# MKM33ZA5 register map
Vendor: Freescale Semiconductor, Inc.; Series: Kinetis_M; File version: 1.6
CPU: CM0PLUS r0p0, little endian, no MPU, no FPU, VTOR, 2 interrupt priority bits
Registers are 8-bit, read-write, reset 0x0 unless marked. A register's access mark holds for its fields unless they carry their own. Offsets are from the block's base; [hi:lo] are bit positions; {n}, {i} and the like mark numbered series.

## XBAR — Crossbar Switch
Base 0x40055000; register names take the prefix XBAR_
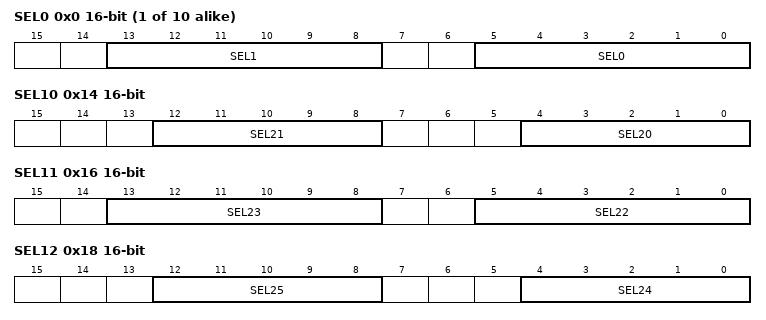
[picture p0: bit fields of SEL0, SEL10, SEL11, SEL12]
{0x0+2i} SEL{i} 16-bit (i=0..9) — Crossbar Select Register {i}
  [13:8] SEL{2i+1}, [5:0] SEL{2i}
0x14 SEL10 16-bit — Crossbar Select Register 10
  [12:8] SEL21, [4:0] SEL20
0x16 SEL11 16-bit — Crossbar Select Register 11
  [13:8] SEL23, [5:0] SEL22
0x18 SEL12 16-bit — Crossbar Select Register 12
  [12:8] SEL25, [4:0] SEL24
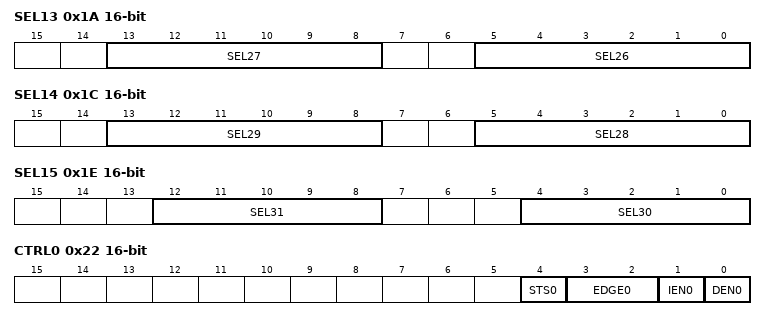
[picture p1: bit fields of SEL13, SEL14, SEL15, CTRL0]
0x1A SEL13 16-bit — Crossbar Select Register 13
  [13:8] SEL27, [5:0] SEL26
0x1C SEL14 16-bit — Crossbar Select Register 14
  [13:8] SEL29, [5:0] SEL28
0x1E SEL15 16-bit — Crossbar Select Register 15
  [12:8] SEL31, [4:0] SEL30
0x20 SEL16 16-bit — Crossbar Select Register 16
  [5:0] SEL32
0x22 CTRL0 16-bit — Crossbar Control Register 0
  [4] STS0 — Edge detection status for XBAR_OUT0
    0=Active edge not yet detected on XBAR_OUT0; 1=Active edge detected on XBAR_OUT0
  [3:2] EDGE0 — Active edge for edge detection on XBAR_OUT0
    0=STS0 never asserts; 1=STS0 asserts on rising edges of XBAR_OUT0; 2=STS0 asserts on falling edges of XBAR_OUT0; 3=STS0 asserts on rising and falling edges of XBAR_OUT0
  [1] IEN0 — Interrupt Enable for XBAR_OUT0
    0=Interrupt disabled; 1=Interrupt enabled
  [0] DEN0 — DMA Enable for XBAR_OUT0
    0=DMA disabled; 1=DMA enabled

## EWM — External Watchdog Monitor
Base 0x40061000; register names take the prefix EWM_
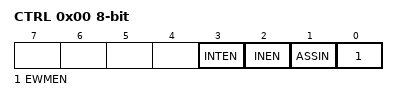
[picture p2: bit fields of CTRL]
0x00 CTRL — Control Register
  [3] INTEN — Interrupt Enable.
  [2] INEN — Input Enable.
  [1] ASSIN — EWM_in's Assertion State Select.
  [0] EWMEN — EWM enable.
0x01 SERV wo — Service Register
  [7:0] SERVICE
0x02 CMPL — Compare Low Register
  [7:0] COMPAREL
0x03 CMPH reset 0xFF — Compare High Register
  [7:0] COMPAREH

## OSC — Oscillator
Base 0x40066000; register names take the prefix OSC_
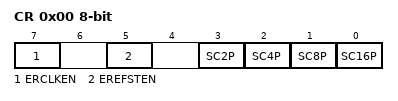
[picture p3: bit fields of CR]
0x00 CR — OSC Control Register
  [7] ERCLKEN — External Reference Enable
    0=External reference clock is inactive; 1=External reference clock is enabled
  [5] EREFSTEN — External Reference Stop Enable
    0=External reference clock is disabled in Stop mode; 1=External reference clock stays enabled in Stop mode if ERCLKEN is set before entering Stop mode
  [3] SC2P — Oscillator 2 pF Capacitor Load Configure
    0=Disable the selection; 1=Add 2 pF capacitor to the oscillator load
  [2] SC4P — Oscillator 4 pF Capacitor Load Configure
    0=Disable the selection; 1=Add 4 pF capacitor to the oscillator load
  [1] SC8P — Oscillator 8 pF Capacitor Load Configure
    0=Disable the selection; 1=Add 8 pF capacitor to the oscillator load
  [0] SC16P — Oscillator 16 pF Capacitor Load Configure
    0=Disable the selection; 1=Add 16 pF capacitor to the oscillator load

## VREF — Voltage Reference
Base 0x4006F000; register names take the prefix VREF_
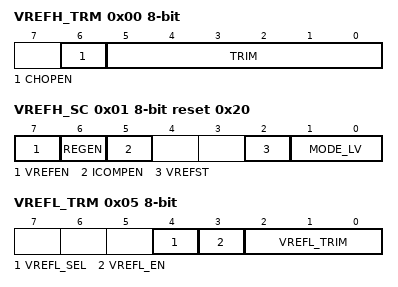
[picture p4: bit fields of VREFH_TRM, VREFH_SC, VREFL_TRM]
0x00 VREFH_TRM (reset mask 0x40) — VREF Trim Register
  [6] CHOPEN — Chop oscillator enable. When set, internal chopping operation is enabled and the internal analog offset will be minimized.
    0=Chop oscillator is disabled; 1=Chop oscillator is enabled
  [5:0] TRIM — Trim bits
    0=Min; 63=Max
0x01 VREFH_SC reset 0x20 — VREF Status and Control Register
  [7] VREFEN — Internal Voltage Reference enable
    0=The module is disabled; 1=The module is enabled
  [6] REGEN — Regulator enable
    0=Internal 1.75 V regulator is disabled; 1=Internal 1.75 V regulator is enabled
  [5] ICOMPEN — Second order curvature compensation enable
    0=Disabled; 1=Enabled
  [2] VREFST ro — Internal Voltage Reference stable
    0=The module is disabled or not stable; 1=The module is stable
  [1:0] MODE_LV — Buffer Mode selection
    0=Bandgap on only, for stabilization and startup; 1=High power buffer mode enabled; 2=Low-power buffer mode enabled
0x05 VREFL_TRM (reset mask 0xF8) — VREFL TRIM Register
  [4] VREFL_SEL
    0=Internal reference; 1=External reference
  [3] VREFL_EN
    0=Disable; 1=Enable
  [2:0] VREFL_TRIM

## Notices in the file
Redistribution and use in source and binary forms, with or without modification,
are permitted provided that the following conditions are met:
o Redistributions of source code must retain the above copyright notice, this list
of conditions and the following disclaimer.
o Redistributions in binary form must reproduce the above copyright notice, this
list of conditions and the following disclaimer in the documentation and/or
other materials provided with the distribution.
o Neither the name of Freescale Semiconductor, Inc. nor the names of its
contributors may be used to endorse or promote products derived from this
software without specific prior written permission.
THIS SOFTWARE IS PROVIDED BY THE COPYRIGHT HOLDERS AND CONTRIBUTORS "AS IS" AND
ANY EXPRESS OR IMPLIED WARRANTIES, INCLUDING, BUT NOT LIMITED TO, THE IMPLIED
WARRANTIES OF MERCHANTABILITY AND FITNESS FOR A PARTICULAR PURPOSE ARE
DISCLAIMED. IN NO EVENT SHALL THE COPYRIGHT HOLDER OR CONTRIBUTORS BE LIABLE FOR
ANY DIRECT, INDIRECT, INCIDENTAL, SPECIAL, EXEMPLARY, OR CONSEQUENTIAL DAMAGES
(INCLUDING, BUT NOT LIMITED TO, PROCUREMENT OF SUBSTITUTE GOODS OR SERVICES;
LOSS OF USE, DATA, OR PROFITS; OR BUSINESS INTERRUPTION) HOWEVER CAUSED AND ON
ANY THEORY OF LIABILITY, WHETHER IN CONTRACT, STRICT LIABILITY, OR TORT
(INCLUDING NEGLIGENCE OR OTHERWISE) ARISING IN ANY WAY OUT OF THE USE OF THIS
SOFTWARE, EVEN IF ADVISED OF THE POSSIBILITY OF SUCH DAMAGE.
